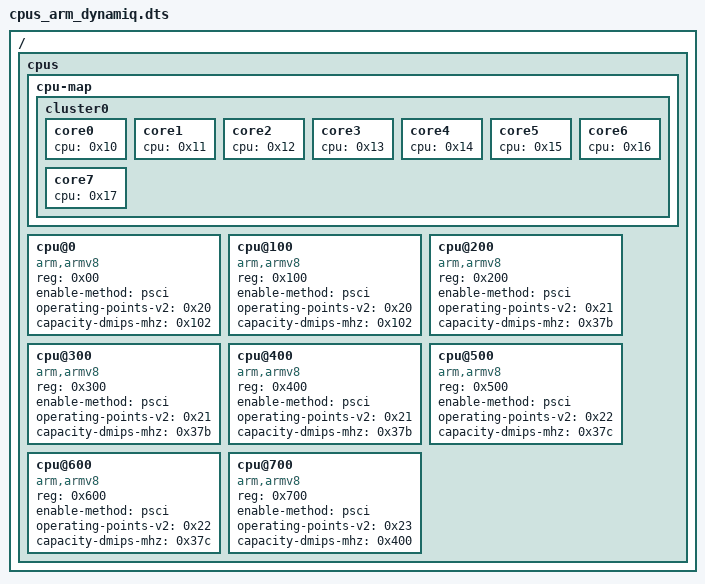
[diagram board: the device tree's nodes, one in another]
// Copyright 2026 The Fuchsia Authors. All rights reserved.
// Use of this source code is governed by a BSD-style license that can be
// found in the LICENSE file.

/dts-v1/;

/ {
    cpus {
        #size-cells = <0>;
        #address-cells = <1>;

        cpu-map {
            cluster0 {
                core0 {
                    cpu = <0x10>;
                };
                core1 {
                    cpu = <0x11>;
                };
                core2 {
                    cpu = <0x12>;
                };
                core3 {
                    cpu = <0x13>;
                };
                core4 {
                    cpu = <0x14>;
                };
                core5 {
                    cpu = <0x15>;
                };
                core6 {
                    cpu = <0x16>;
                };
                core7 {
                    cpu = <0x17>;
                };
            };
        };

        cpu@0 {
            device_type = "cpu";
            compatible = "arm,armv8";
            reg = <0x00>;
            enable-method = "psci";
            operating-points-v2 = <0x20>;
            capacity-dmips-mhz = <0x102>;
            phandle = <0x10>;
        };

        cpu@100 {
            device_type = "cpu";
            compatible = "arm,armv8";
            reg = <0x100>;
            enable-method = "psci";
            operating-points-v2 = <0x20>;
            capacity-dmips-mhz = <0x102>;
            phandle = <0x11>;
        };

        cpu@200 {
            device_type = "cpu";
            compatible = "arm,armv8";
            reg = <0x200>;
            enable-method = "psci";
            operating-points-v2 = <0x21>;
            capacity-dmips-mhz = <0x37b>;
            phandle = <0x12>;
        };

        cpu@300 {
            device_type = "cpu";
            compatible = "arm,armv8";
            reg = <0x300>;
            enable-method = "psci";
            operating-points-v2 = <0x21>;
            capacity-dmips-mhz = <0x37b>;
            phandle = <0x13>;
        };

        cpu@400 {
            device_type = "cpu";
            compatible = "arm,armv8";
            reg = <0x400>;
            enable-method = "psci";
            operating-points-v2 = <0x21>;
            capacity-dmips-mhz = <0x37b>;
            phandle = <0x14>;
        };

        cpu@500 {
            device_type = "cpu";
            compatible = "arm,armv8";
            reg = <0x500>;
            enable-method = "psci";
            operating-points-v2 = <0x22>;
            capacity-dmips-mhz = <0x37c>;
            phandle = <0x15>;
        };

        cpu@600 {
            device_type = "cpu";
            compatible = "arm,armv8";
            reg = <0x600>;
            enable-method = "psci";
            operating-points-v2 = <0x22>;
            capacity-dmips-mhz = <0x37c>;
            phandle = <0x16>;
        };

        cpu@700 {
            device_type = "cpu";
            compatible = "arm,armv8";
            reg = <0x700>;
            enable-method = "psci";
            operating-points-v2 = <0x23>;
            capacity-dmips-mhz = <0x400>;
            phandle = <0x17>;
        };
    };
};
